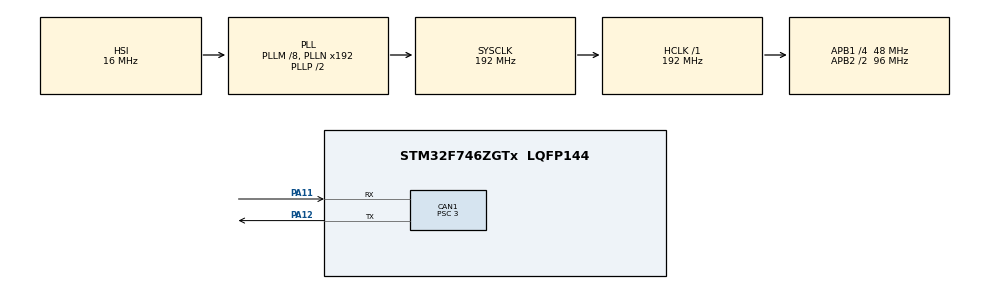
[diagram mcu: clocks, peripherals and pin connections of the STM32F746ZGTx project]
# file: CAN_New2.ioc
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CAN1.BS1=CAN_BS1_13TQ
CAN1.BS2=CAN_BS2_2TQ
CAN1.CalculateTimeQuantum=62.5
CAN1.Prescaler=3
Mcu.Family=STM32F7
Mcu.Name=STM32F746ZGTx
Mcu.Package=LQFP144
NVIC.CAN1_RX0_IRQn=true\:0\:0\:false\:false\:true\:true\:true
NVIC.PriorityGroup=NVIC_PRIORITYGROUP_4
NVIC.TIM6_DAC_IRQn=true\:0\:0\:false\:false\:true\:true\:true
PA11.Mode=Master
PA11.Signal=CAN1_RX
PA12.Mode=Master
PA12.Signal=CAN1_TX
ProjectManager.HeapSize=0x200
ProjectManager.StackSize=0x400
ProjectManager.TargetToolchain=EWARM V8.32
RCC.AHBFreq_Value=192000000
RCC.APB1CLKDivider=RCC_HCLK_DIV4
RCC.APB1Freq_Value=48000000
RCC.APB1TimFreq_Value=96000000
RCC.APB2CLKDivider=RCC_HCLK_DIV2
RCC.APB2Freq_Value=96000000
RCC.APB2TimFreq_Value=192000000
RCC.CortexFreq_Value=192000000
RCC.HCLKFreq_Value=192000000
RCC.HSE_VALUE=25000000
RCC.HSI_VALUE=16000000
RCC.LSE_VALUE=32768
RCC.PLLM=8
RCC.SYSCLKFreq_VALUE=192000000
RCC.SYSCLKSource=RCC_SYSCLKSOURCE_PLLCLK
RCC.USBFreq_Value=192000000
RCC.VCOOutputFreq_Value=384000000
TIM6.Period=100-1
TIM6.Prescaler=9600-1
VP_TIM6_VS_ClockSourceINT.Mode=Enable_Timer
board=custom

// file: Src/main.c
/* USER CODE BEGIN Header */
/**
  ******************************************************************************
  * @file           : main.c
  * @brief          : Main program body
  ******************************************************************************
  * @attention
  *
  * <h2><center>&copy; Copyright (c) 2020 STMicroelectronics.
  * All rights reserved.</center></h2>
  *
  * This software component is licensed by ST under BSD 3-Clause license,
  * the "License"; You may not use this file except in compliance with the
  * License. You may obtain a copy of the License at:
  *                        opensource.org/licenses/BSD-3-Clause
  *
  ******************************************************************************
  */
/* USER CODE END Header */

#include "main.h"

/* USER CODE BEGIN PTD */
 CAN_FilterTypeDef canFilter1;
 CAN_RxHeaderTypeDef canRxHeader;
 CAN_TxHeaderTypeDef canTxHeader;
 uint8_t can1Rx0Data[8];
 uint8_t can1Tx0Data[8];
 uint8_t can1_rx0_flag;
 uint8_t can1_tx_flag;
 uint32_t TxMailBox;

int temp[8];
int main_cnt;
int ff,fff;

void CAN_ini();

extern CAN_RxHeaderTypeDef rxHeader; // F1 V1.23.0
extern CAN_TxHeaderTypeDef txHeader;
extern bool can_rfg; // 수신플래그
extern uint8_t rxData[8]; // 수신버퍼입니다
extern uint8_t txData[8]; //송신버퍼입니다
extern uint8_t can_ct1, can_ct2; // for led
extern uint32_t txMailBox;

extern void put_can(void);
/* USER CODE END PTD */

CAN_HandleTypeDef hcan1;

TIM_HandleTypeDef htim6;

void SystemClock_Config(void);
static void MX_GPIO_Init(void);
static void MX_CAN1_Init(void);
static void MX_TIM6_Init(void);

int main(void)
{

  /* MCU Configuration--------------------------------------------------------*/

  /* Reset of all peripherals, Initializes the Flash interface and the Systick. */
  HAL_Init();

  /* Configure the system clock */
  SystemClock_Config();

  /* Initialize all configured peripherals */
  MX_GPIO_Init();
  MX_CAN1_Init();
  MX_TIM6_Init();
  /* USER CODE BEGIN 2 */

  /*can1Tx0Data[0] = 0;
  can1Tx0Data[1] = 1;
  can1Tx0Data[2] = 2;
  can1Tx0Data[3] = 3;
  can1Tx0Data[4] = 4;
  can1Tx0Data[5] = 5;
  can1Tx0Data[6] = 6;
  can1Tx0Data[7] = 7;

  canFilter1.FilterMaskIdHigh = 0x7F3 << 5;
  canFilter1.FilterIdHigh = 0x106 << 5;
  canFilter1.FilterMaskIdLow = 0x7F3 << 5;
  canFilter1.FilterIdLow = 0x106 << 5;
  canFilter1.FilterMode = CAN_FILTERMODE_IDMASK;
  canFilter1.FilterScale = CAN_FILTERSCALE_16BIT;
  canFilter1.FilterFIFOAssignment = CAN_FILTER_FIFO0;
  canFilter1.FilterBank = 0;
  canFilter1.FilterActivation = ENABLE;
  HAL_CAN_ConfigFilter(&hcan1,&canFilter1);*/

  ff = 0;
  can1_rx0_flag = 0;
  temp[0] = 0;

  CAN_ini();

  HAL_CAN_Start(&hcan1);
  HAL_CAN_ActivateNotification(&hcan1,CAN_IT_RX_FIFO0_MSG_PENDING);

  HAL_TIM_Base_Start_IT(&htim6);
  /* USER CODE END 2 */

  /* Infinite loop */
  while (1)
  {

    /* USER CODE BEGIN 3 */
    main_cnt++;
    //if(ff == 1)
    //  fff = 2;

    //if(can1_tx_flag == 1){
    if(main_cnt / 500000 == 1){
      //can1_tx_flag = 0;
      fff = 3;

      /*canTxHeader.StdId = 0x102;
      canTxHeader.RTR = CAN_RTR_DATA;
      canTxHeader.IDE = CAN_ID_STD;
      canTxHeader.DLC = 8;

      TxMailBox = HAL_CAN_GetTxMailboxesFreeLevel(&hcan1);
      ff = HAL_CAN_AddTxMessage(&hcan1,&canTxHeader,&can1Tx0Data[0],&TxMailBox);*/
      main_cnt = 0 ;
    }
  }
  /* USER CODE END 3 */
}

void SystemClock_Config(void)
{
  RCC_OscInitTypeDef RCC_OscInitStruct = {0};
  RCC_ClkInitTypeDef RCC_ClkInitStruct = {0};

  /** Configure the main internal regulator output voltage
  */
  __HAL_RCC_PWR_CLK_ENABLE();
  __HAL_PWR_VOLTAGESCALING_CONFIG(PWR_REGULATOR_VOLTAGE_SCALE1);
  /** Initializes the CPU, AHB and APB busses clocks
  */
  RCC_OscInitStruct.OscillatorType = RCC_OSCILLATORTYPE_HSI;
  RCC_OscInitStruct.HSIState = RCC_HSI_ON;
  RCC_OscInitStruct.HSICalibrationValue = RCC_HSICALIBRATION_DEFAULT;
  RCC_OscInitStruct.PLL.PLLState = RCC_PLL_ON;
  RCC_OscInitStruct.PLL.PLLSource = RCC_PLLSOURCE_HSI;
  RCC_OscInitStruct.PLL.PLLM = 8;
  RCC_OscInitStruct.PLL.PLLN = 192;
  RCC_OscInitStruct.PLL.PLLP = RCC_PLLP_DIV2;
  RCC_OscInitStruct.PLL.PLLQ = 2;
  if (HAL_RCC_OscConfig(&RCC_OscInitStruct) != HAL_OK)
  {
    Error_Handler();
  }
  /** Activate the Over-Drive mode
  */
  if (HAL_PWREx_EnableOverDrive() != HAL_OK)
  {
    Error_Handler();
  }
  /** Initializes the CPU, AHB and APB busses clocks
  */
  RCC_ClkInitStruct.ClockType = RCC_CLOCKTYPE_HCLK|RCC_CLOCKTYPE_SYSCLK
                              |RCC_CLOCKTYPE_PCLK1|RCC_CLOCKTYPE_PCLK2;
  RCC_ClkInitStruct.SYSCLKSource = RCC_SYSCLKSOURCE_PLLCLK;
  RCC_ClkInitStruct.AHBCLKDivider = RCC_SYSCLK_DIV1;
  RCC_ClkInitStruct.APB1CLKDivider = RCC_HCLK_DIV4;
  RCC_ClkInitStruct.APB2CLKDivider = RCC_HCLK_DIV2;

  if (HAL_RCC_ClockConfig(&RCC_ClkInitStruct, FLASH_LATENCY_6) != HAL_OK)
  {
    Error_Handler();
  }
}

static void MX_CAN1_Init(void)
{

  hcan1.Instance = CAN1;
  hcan1.Init.Prescaler = 3;
  hcan1.Init.Mode = CAN_MODE_NORMAL;
  hcan1.Init.SyncJumpWidth = CAN_SJW_1TQ;
  hcan1.Init.TimeSeg1 = CAN_BS1_13TQ;
  hcan1.Init.TimeSeg2 = CAN_BS2_2TQ;
  hcan1.Init.TimeTriggeredMode = DISABLE;
  hcan1.Init.AutoBusOff = DISABLE;
  hcan1.Init.AutoWakeUp = DISABLE;
  hcan1.Init.AutoRetransmission = DISABLE;
  hcan1.Init.ReceiveFifoLocked = DISABLE;
  hcan1.Init.TransmitFifoPriority = DISABLE;
  if (HAL_CAN_Init(&hcan1) != HAL_OK)
  {
    Error_Handler();
  }

}

static void MX_TIM6_Init(void)
{

  TIM_MasterConfigTypeDef sMasterConfig = {0};

  htim6.Instance = TIM6;
  htim6.Init.Prescaler = 9600-1;
  htim6.Init.CounterMode = TIM_COUNTERMODE_UP;
  htim6.Init.Period = 100-1;
  htim6.Init.AutoReloadPreload = TIM_AUTORELOAD_PRELOAD_DISABLE;
  if (HAL_TIM_Base_Init(&htim6) != HAL_OK)
  {
    Error_Handler();
  }
  sMasterConfig.MasterOutputTrigger = TIM_TRGO_RESET;
  sMasterConfig.MasterSlaveMode = TIM_MASTERSLAVEMODE_DISABLE;
  if (HAL_TIMEx_MasterConfigSynchronization(&htim6, &sMasterConfig) != HAL_OK)
  {
    Error_Handler();
  }

}

static void MX_GPIO_Init(void)
{

  /* GPIO Ports Clock Enable */
  __HAL_RCC_GPIOA_CLK_ENABLE();

}

/* USER CODE BEGIN 4 */

/*void HAL_CAN_RxFifio0MsgPendingCallback(CAN_HandleTypeDef *hcan){

  if(hcan->Instance == CAN1){
    HAL_CAN_GetRxMessage(&hcan1,CAN_RX_FIFO0,&canRxHeader,&can1Rx0Data[0]);
    can1_rx0_flag = 1;

    for(int i = 0 ; i < 8 ;i++)
      temp[i] = can1Rx0Data[i];
  }
}*/

int canRx_cnt;
void HAL_CAN_RxFifo0MsgPendingCallback(CAN_HandleTypeDef* hcan) // 인터럽트 함수입니다
{
   if (hcan->Instance == CAN1) {

      HAL_CAN_GetRxMessage (&hcan1, CAN_RX_FIFO0, &rxHeader, &rxData[0]);
      can_rfg = true; // can수신플래그 켜기(ON)를 합니다

      //put_can(); // 응답을 합니다
      canRx_cnt++;

   }
}

void CAN_ini(void) // 필터 초기화 함수입니다
{
  CAN_FilterTypeDef sFilterConfig;

  sFilterConfig.FilterBank = 0;
  sFilterConfig.FilterMode = CAN_FILTERMODE_IDMASK;
  sFilterConfig.FilterScale = CAN_FILTERSCALE_32BIT;
  sFilterConfig.FilterIdHigh = 0x0000;
  sFilterConfig.FilterIdLow = 0x0000;
  sFilterConfig.FilterMaskIdHigh = 0x0000;
  sFilterConfig.FilterMaskIdLow = 0x0000;
  sFilterConfig.FilterFIFOAssignment = CAN_RX_FIFO0;
  sFilterConfig.FilterActivation = ENABLE;
  sFilterConfig.SlaveStartFilterBank = 14;
  HAL_CAN_ConfigFilter(&hcan1, &sFilterConfig);
}

/* USER CODE END 4 */

void Error_Handler(void)
{
}

/************************ (C) COPYRIGHT STMicroelectronics *****END OF FILE****/
